# STM32F765BGT6 register map
File version: 1.0
Registers are 32-bit, access not given, reset 0x0 unless marked. A register's access mark holds for its fields unless they carry their own. Offsets are from the block's base; [hi:lo] are bit positions; {n}, {i} and the like mark numbered series; 'fields as' and 'values as' point back to an identical list.

## RTC
Base 0x40002800
0x00 TR
  [22] PM, [21:20] HT, [19:16] HU, [14:12] MNT, [11:8] MNU, [31:7] s, [6:4] ST, [3:0] SU
0x04 DR
  [23:20] YT, [19:16] YU, [15:13] WDU, [12] MT, [11:8] MU, [31:6] s, [5:4] DT, [3:0] DU
0x08 CR
  [24] ITSE, [23] COE, [22:21] OSEL, [20] POL, [19] COSEL, [18] BKP, [17] SUB1H, [16] ADD1H, [15] TSIE, [14] WUTIE, [13] ALRBIE, [12] ALRAIE, [11] TSE, [10] WUTE, [9] ALRBE, [8] ALRAE, [31:7] s, [6] FMT, [5] BYPSHAD, [4] REFCKON, [3] TSEDGE, [2:0] WUCKSEL
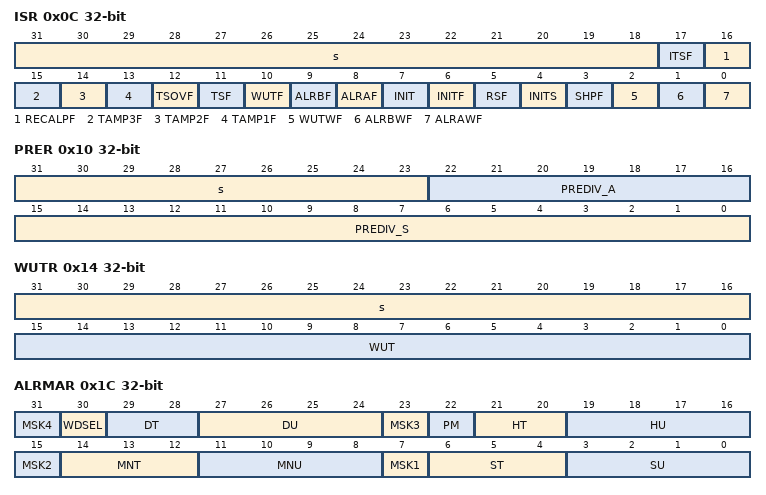
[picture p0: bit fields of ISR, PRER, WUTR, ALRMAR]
0x0C ISR
  [31:18] s, [17] ITSF, [16] RECALPF, [15] TAMP3F, [14] TAMP2F, [13] TAMP1F, [12] TSOVF, [11] TSF, [10] WUTF, [9] ALRBF, [8] ALRAF, [7] INIT, [6] INITF, [5] RSF, [4] INITS, [3] SHPF, [2] WUTWF, [1] ALRBWF, [0] ALRAWF
0x10 PRER
  [31:23] s, [22:16] PREDIV_A, [15:0] PREDIV_S
0x14 WUTR
  [31:16] s, [15:0] WUT
0x1C ALRMAR
  [8n-1] MSK{n} (n=1..4), [30] WDSEL, [29:28] DT, [27:24] DU, [22] PM, [21:20] HT, [19:16] HU, [14:12] MNT, [11:8] MNU, [6:4] ST, [3:0] SU
0x20 ALRMBR
  [31] MSK4, [30] WDSEL, [29:28] DT, [27:24] DU, [23] MSK3, [22] PM, [21:20] HT, [19:16] HU, [14:12] MNT, [11:8] MNU, [15:7] MSK2, [6:4] ST, [3:0] SU
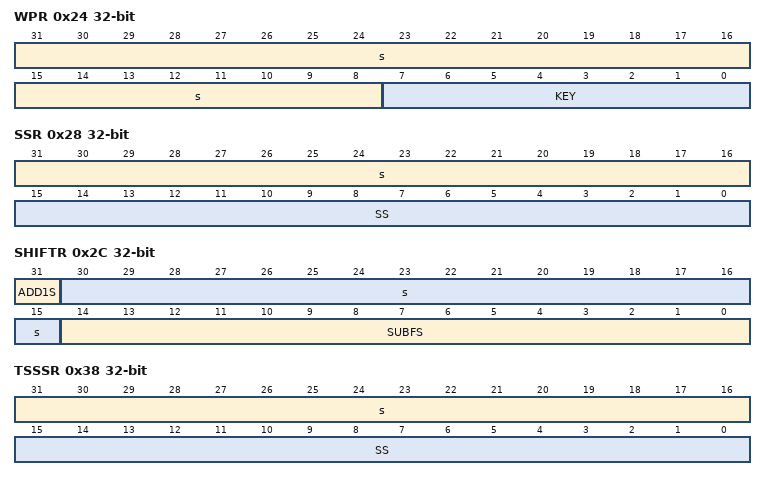
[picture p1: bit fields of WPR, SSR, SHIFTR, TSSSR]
0x24 WPR
  [31:8] s, [7:0] KEY
0x28 SSR
  [31:16] s, [15:0] SS
0x2C SHIFTR
  [31] ADD1S, [30:15] s, [14:0] SUBFS
0x30 TSTR
  fields as TR
0x34 TSDR
  [15:13] WDU, [12] MT, [11:8] MU, [31:6] s, [5:4] DT, [3:0] DU
0x38 TSSSR
  [31:16] s, [15:0] SS
0x3C CALR
  [15] CALP, [14] CALW8, [13] CALW16, [31:9] s, [8:0] CALM
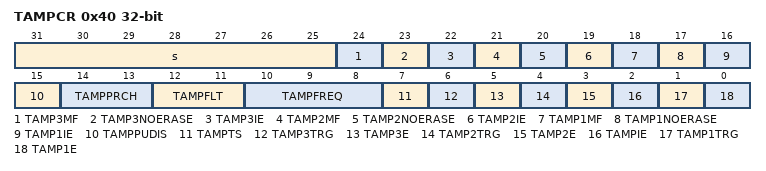
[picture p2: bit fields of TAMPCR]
0x40 TAMPCR
  [31:25] s, [24] TAMP3MF, [23] TAMP3NOERASE, [22] TAMP3IE, [21] TAMP2MF, [20] TAMP2NOERASE, [19] TAMP2IE, [18] TAMP1MF, [17] TAMP1NOERASE, [16] TAMP1IE, [15] TAMPPUDIS, [14:13] TAMPPRCH, [12:11] TAMPFLT, [10:8] TAMPFREQ, [7] TAMPTS, [6] TAMP3TRG, [5] TAMP3E, [4] TAMP2TRG, [3] TAMP2E, [2] TAMPIE, [1] TAMP1TRG, [0] TAMP1E
0x44 ALRMASSR
  [27:24] MASKSS, [31:15] s, [14:0] SS
0x48 ALRMBSSR
  [27:24] MASKSS, [31:15] s, [14:0] SS
0x4C OR
  [3] RTC_ALARM_TYPE, [2:1] TSINSEL, [31:0] s
{0x50+4i} BKP{i}R (i=0..31)
  [31:0] BKP

## BKP
Base 0x40002800
Registers as RTC; these are added or differ:
0x08 CR
  fields as RTC.CR
0x4C OR
  [3] RTC_ALARM_TYPE, [2:1] TSINSEL, [31:0] s
{0x50+4i} BKP{i}R (i=0..31)
  [31:0] BKP

## WWDG
Base 0x40002C00
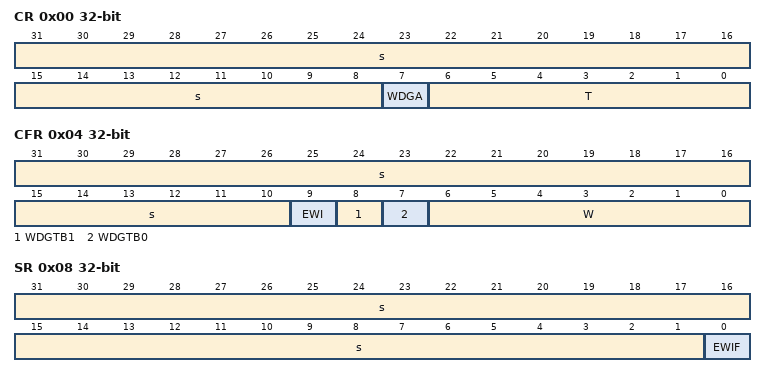
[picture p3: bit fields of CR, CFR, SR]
0x00 CR
  [31:8] s, [7] WDGA, [6:0] T
0x04 CFR
  [31:10] s, [9] EWI, [8] WDGTB1, [7] WDGTB0, [6:0] W
0x08 SR
  [31:1] s, [0] EWIF

## IWDG
Base 0x40003000
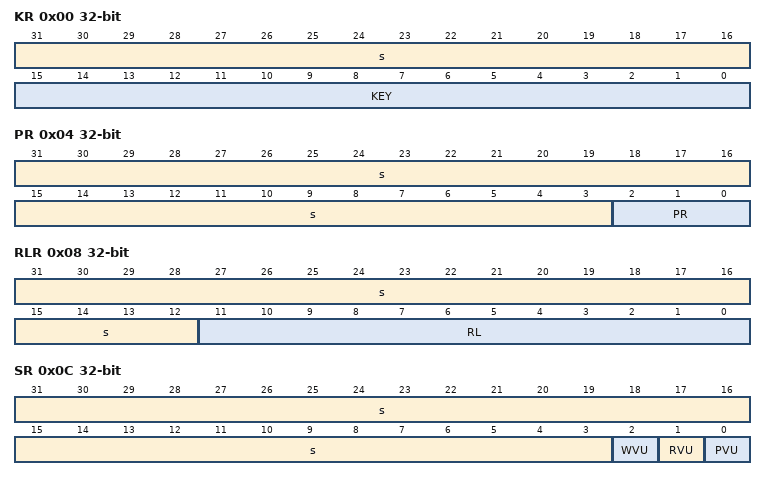
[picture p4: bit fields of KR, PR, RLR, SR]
0x00 KR
  [31:16] s, [15:0] KEY
0x04 PR
  [31:3] s, [2:0] PR
0x08 RLR
  [31:12] s, [11:0] RL
0x0C SR
  [31:3] s, [2] WVU, [1] RVU, [0] PVU
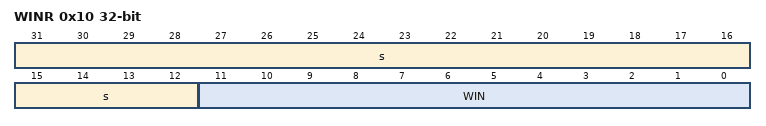
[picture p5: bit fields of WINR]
0x10 WINR
  [31:12] s, [11:0] WIN

## CAN3
Base 0x40003400
Same registers: CAN1 0x40006400, CAN2 0x40006800
0x00 MCR
  [16] DBF, [15] RESET, [31:8] s, [7] TTCM, [6] ABOM, [5] AWUM, [4] NART, [3] RFLM, [2] TXFP, [1] SLEEP, [0] INRQ
0x04 MSR
  [11] RX, [10] SAMP, [9] RXM, [8] TXM, [31:5] s, [4] SLAKI, [3] WKUI, [2] ERRI, [1] SLAK, [0] INAK
0x08 TSR
  [31:29] LOW, [28:26] TME, [25:24] CODE, [23] ABRQ2, [19] TERR2, [18] ALST2, [17] TXOK2, [16] RQCP2, [15] ABRQ1, [11] TERR1, [10] ALST1, [9] TXOK1, [8] RQCP1, [7] ABRQ0, [22:4] s, [3] TERR0, [2] ALST0, [1] TXOK0, [0] RQCP0
0x0C RF0R
  [5] RFOM0, [4] FOVR0, [3] FULL0, [31:2] s, [1:0] FMP0
0x10 RF1R
  [5] RFOM1, [4] FOVR1, [3] FULL1, [31:2] s, [1:0] FMP1
0x14 IER
  [17] SLKIE, [16] WKUIE, [15] ERRIE, [11] LECIE, [10] BOFIE, [9] EPVIE, [8] EWGIE, [31:7] s, [6] FOVIE1, [5] FFIE1, [4] FMPIE1, [3] FOVIE0, [2] FFIE0, [1] FMPIE0, [0] TMEIE
0x18 ESR
  [31:24] REC, [23:16] TEC, [6:4] LEC, [15:3] s, [2] BOFF, [1] EPVF, [0] EWGF
0x1C BTR
  [31] SILM, [30] LBKM, [25:24] SJW, [22:20] TS2, [19:16] TS1, [29:10] s, [9:0] BRP
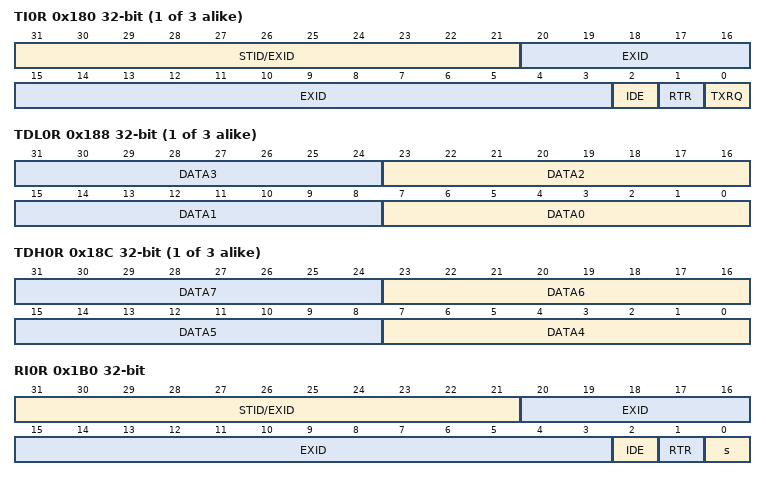
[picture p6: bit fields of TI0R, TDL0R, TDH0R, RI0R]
{0x180+0x10*i} TI{i}R (i=0..2)
  [31:21] STID/EXID, [20:3] EXID, [2] IDE, [1] RTR, [0] TXRQ
{0x184+0x10*i} TDT{i}R (i=0..2)
  [31:16] TIME, [8] TGT, [15:4] s, [3:0] DLC
{0x188+0x10*i} TDL{i}R (i=0..2)
  [8n+7:8n] DATA{n} (n=0..3)
{0x18C+0x10*i} TDH{i}R (i=0..2)
  [8n-25:8n-32] DATA{n} (n=4..7)
0x1B0 RI0R
  [31:21] STID/EXID, [20:3] EXID, [2] IDE, [1] RTR, [0] s
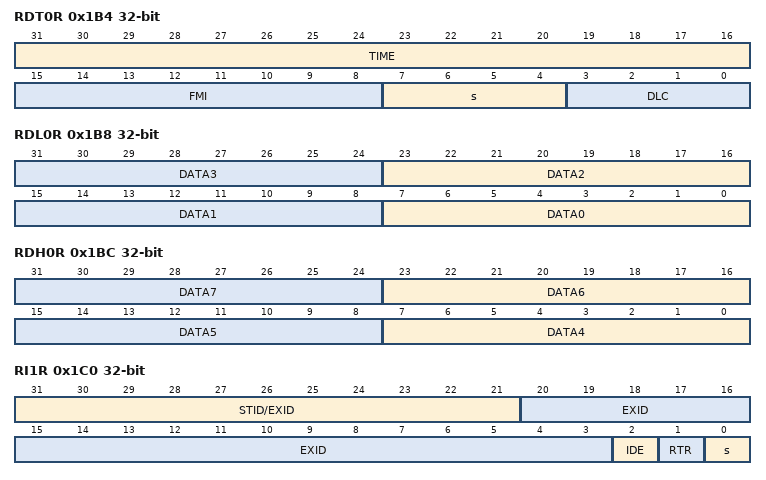
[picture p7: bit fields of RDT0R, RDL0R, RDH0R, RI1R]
0x1B4 RDT0R
  [31:16] TIME, [15:8] FMI, [7:4] s, [3:0] DLC
0x1B8 RDL0R
  [8n+7:8n] DATA{n} (n=0..3)
0x1BC RDH0R
  [8n-25:8n-32] DATA{n} (n=4..7)
0x1C0 RI1R
  [31:21] STID/EXID, [20:3] EXID, [2] IDE, [1] RTR, [0] s
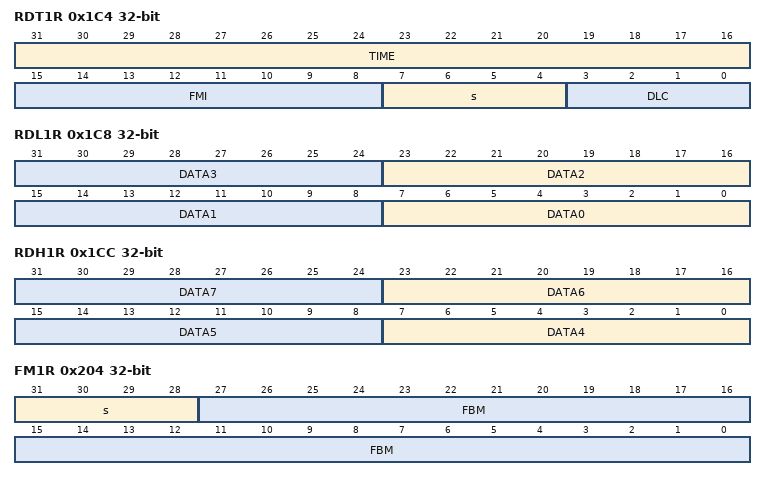
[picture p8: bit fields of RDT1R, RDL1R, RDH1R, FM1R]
0x1C4 RDT1R
  [31:16] TIME, [15:8] FMI, [7:4] s, [3:0] DLC
0x1C8 RDL1R
  [8n+7:8n] DATA{n} (n=0..3)
0x1CC RDH1R
  [8n-25:8n-32] DATA{n} (n=4..7)
0x200 FMR
  [13:8] CANSB, [31:1] s, [0] FINIT
0x204 FM1R
  [31:28] s, [27:0] FBM
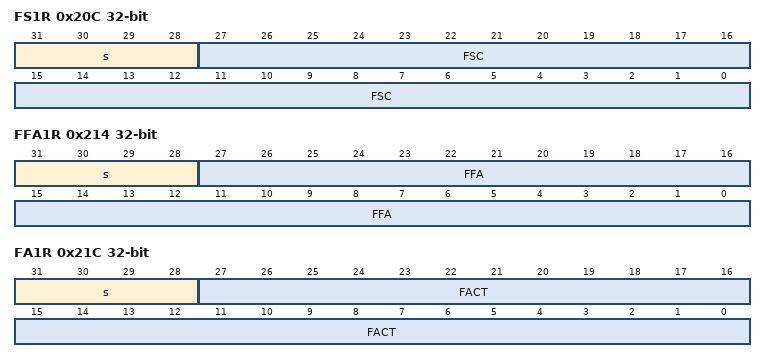
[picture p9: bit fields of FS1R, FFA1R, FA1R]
0x20C FS1R
  [31:28] s, [27:0] FSC
0x214 FFA1R
  [31:28] s, [27:0] FFA
0x21C FA1R
  [31:28] s, [27:0] FACT
0x240 F0R1
  [31:0] FB
0x244 F0R2
  [31:0] FB
0x248 F1R1
  [31:0] FB
0x24C F1R2
  [31:0] FB
0x318 F27R1
  [31:0] FB
0x31C F27R2
  [31:0] FB
